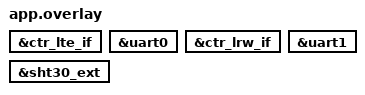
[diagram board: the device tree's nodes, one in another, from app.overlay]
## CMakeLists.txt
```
#
# Copyright (c) 2024 HARDWARIO a.s.
#
#  SPDX-License-Identifier: LicenseRef-HARDWARIO-5-Clause
#

cmake_minimum_required(VERSION 3.20.0)

set(ENV{FW_BUNDLE} "com.hardwario.chester.clime")
set(ENV{FW_VERSION} "v1.0.0")
set(ENV{FW_NAME} "CHESTER Clime")

find_package(Zephyr REQUIRED HINTS $ENV{ZEPHYR_BASE})

project(chester-clime)

add_custom_command(
    COMMAND ../../../scripts/gen-msg-key.py ../codec/cbor-decoder.yaml ../src/msg_key.h
    OUTPUT ../src/msg_key.h
    MAIN_DEPENDENCY ../codec/cbor-decoder.yaml
)

target_sources(app PRIVATE src/app_sensor.c)
target_sources(app PRIVATE src/main.c)
target_sources(app PRIVATE src/app_shell.c)
target_sources(app PRIVATE src/app_init.c)
target_sources(app PRIVATE src/app_data.c)
target_sources(app PRIVATE src/app_power.c)
target_sources(app PRIVATE src/app_send.c)
target_sources(app PRIVATE src/app_config.c)
target_sources(app PRIVATE src/app_work.c)
target_sources(app PRIVATE src/app_handler.c)
target_sources(app PRIVATE src/app_backup.c)
target_sources(app PRIVATE src/app_cbor.c)
```

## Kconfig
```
#
# Copyright (c) 2024 HARDWARIO a.s.
#
# SPDX-License-Identifier: LicenseRef-HARDWARIO-5-Clause
#

menu "Application"

# CHESTER CLIME Project | CLIME Variant 

# LTE 
config SHIELD_CTR_LTE
	bool "Enable SHIELD_CTR_LTE"
	default y 

config CTR_LTE
	default y
# LRW 
config SHIELD_CTR_LRW
	bool "Enable SHIELD_CTR_LRW"
	default y 

config CTR_LRW
	default y
# S2 
config SHIELD_CTR_S2
	bool "Enable SHIELD_CTR_S2"
	default y 

config CTR_HYGRO
	default y

endmenu

menu "Zephyr Kernel"
source "Kconfig.zephyr"
endmenu
```

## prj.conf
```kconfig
#
# Copyright (c) 2024 HARDWARIO a.s.
#
#  SPDX-License-Identifier: LicenseRef-HARDWARIO-5-Clause
#

# Configurations
CONFIG_ADC_SHELL=y
CONFIG_CTR_ACCEL=y
CONFIG_CTR_BATT=y
CONFIG_CTR_BUTTON=y
CONFIG_CTR_BLE=y
CONFIG_CTR_BUF=y
CONFIG_CTR_DEFAULTS=y
CONFIG_CTR_INFO=y
CONFIG_CTR_LED=y
CONFIG_CTR_LOG=y
CONFIG_CTR_RTC=y
CONFIG_CTR_THERM=y
CONFIG_CTR_WDOG=y
CONFIG_TINYCRYPT=y
CONFIG_TINYCRYPT_SHA256=y
CONFIG_ZCBOR=y
CONFIG_ZCBOR_STOP_ON_ERROR=y
CONFIG_CTR_LTE_CLKSYNC=y

# Extra configurations
CONFIG_ADC_TLA2021_INIT_PRIORITY=60
CONFIG_ADC_NRFX_SAADC=n
CONFIG_ADC_SHELL=n
CONFIG_NEWLIB_LIBC_NANO=n

# USER CODE BEGIN Config 
# USER CODE END Config
```

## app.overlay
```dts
/*
 * Copyright (c) 2024 HARDWARIO a.s.
 *
 * SPDX-License-Identifier: LicenseRef-HARDWARIO-5-Clause
 */

/* CHESTER CLIME Project | CLIME Variant */

/* LTE  */
&ctr_lte_if {
	status = "okay";
};

&uart0 {
	status = "okay";
};
/* LRW   */
&ctr_lrw_if {
	status = "okay";
};

&uart1 {
	status = "okay";
};
/* S2  */
&sht30_ext {
	status = "okay";
};
```

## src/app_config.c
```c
/*
 * Copyright (c) 2024 HARDWARIO a.s.
 *
 * SPDX-License-Identifier: LicenseRef-HARDWARIO-5-Clause
 */

#include "app_config.h"

/* CHESTER includes */
#include <chester/ctr_config.h>

/* Zephyr includes */
#include <zephyr/init.h>
#include <zephyr/kernel.h>
#include <zephyr/logging/log.h>
#include <zephyr/settings/settings.h>
#include <zephyr/shell/shell.h>

/* Standard includes */
#include <ctype.h>
#include <stdbool.h>
#include <stdio.h>
#include <stdlib.h>
#include <string.h>

/* USER CODE BEGIN Includes */
/* USER CODE END Includes */

LOG_MODULE_REGISTER(app_config, LOG_LEVEL_DBG);

#define SETTINGS_PFX "chester-clime"

struct app_config g_app_config;

static struct app_config m_app_config_interim = {
	.interval_sample = 60,
	.interval_aggreg = 300,
	.interval_report = 1800,
	.event_report_delay = 1,
	.event_report_rate = 30,
	.backup_report_connected = true,
	.backup_report_disconnected = true,
	.mode = APP_CONFIG_MODE_LTE,

	/* USER CODE BEGIN Struct Variables */
	/* USER CODE END Struct Variables */
};

/* USER CODE BEGIN Variables */
/* USER CODE END Variables */

static void print_app_config_mode(const struct shell *shell)
{
	const char *mode;
	switch (m_app_config_interim.mode) {
	case APP_CONFIG_MODE_NONE:
		mode = "none";
		break;
	case APP_CONFIG_MODE_LTE:
		mode = "lte";
		break;
	case APP_CONFIG_MODE_LRW:
		mode = "lrw";
		break;
	default:
		mode = "(unknown)";
		break;
	}

	shell_print(shell, "app config mode %s", mode);
}

int app_config_cmd_config_mode(const struct shell *shell, size_t argc, char **argv)
{
	if (argc == 1) {
		print_app_config_mode(shell);
		return 0;
	}

	if (argc == 2) {
		if (!strcmp("none", argv[1])) {
			m_app_config_interim.mode = APP_CONFIG_MODE_NONE;
			return 0;
		}

		if (!strcmp("lte", argv[1])) {
			m_app_config_interim.mode = APP_CONFIG_MODE_LTE;
			return 0;
		}

		if (!strcmp("lrw", argv[1])) {
			m_app_config_interim.mode = APP_CONFIG_MODE_LRW;
			return 0;
		}

		shell_error(shell, "invalid option");

		return -EINVAL;
	}

	shell_help(shell);

	return -EINVAL;
}

static void print_interval_sample(const struct shell *shell)
{
	shell_print(shell, "app config interval-sample  %d",
			m_app_config_interim.interval_sample);
}

int app_config_cmd_config_interval_sample(const struct shell *shell, size_t argc, char **argv)
{
	if (argc == 1) {
		print_interval_sample(shell);
		return 0;
	}
	if (argc == 2) {
		size_t len = strlen(argv[1]);
		for (size_t i = 0; i < len; i++) {
			if (!isdigit((int)argv[1][i])) {
				shell_error(shell, "invalid format");
				return -EINVAL;
			}
		}
		long value = strtol(argv[1], NULL, 10);
		if (value < 1 || value > 86400) {
			shell_error(shell, "invalid range");
			return -EINVAL;
		}
		m_app_config_interim.interval_sample = (int)value;
		return 0;
	}
	shell_help(shell);
	return -EINVAL;
}

static void print_interval_aggreg(const struct shell *shell)
{
	shell_print(shell, "app config interval-aggreg  %d",
			m_app_config_interim.interval_aggreg);
}

int app_config_cmd_config_interval_aggreg(const struct shell *shell, size_t argc, char **argv)
{
	if (argc == 1) {
		print_interval_aggreg(shell);
		return 0;
	}
	if (argc == 2) {
		size_t len = strlen(argv[1]);
		for (size_t i = 0; i < len; i++) {
			if (!isdigit((int)argv[1][i])) {
				shell_error(shell, "invalid format");
				return -EINVAL;
			}
		}
		long value = strtol(argv[1], NULL, 10);
		if (value < 1 || value > 86400) {
			shell_error(shell, "invalid range");
			return -EINVAL;
		}
		m_app_config_interim.interval_aggreg = (int)value;
		return 0;
	}
	shell_help(shell);
	return -EINVAL;
}

static void print_interval_report(const struct shell *shell)
{
	shell_print(shell, "app config interval-report  %d",
			m_app_config_interim.interval_report);
}

int app_config_cmd_config_interval_report(const struct shell *shell, size_t argc, char **argv)
{
	if (argc == 1) {
		print_interval_report(shell);
		return 0;
	}
	if (argc == 2) {
		size_t len = strlen(argv[1]);
		for (size_t i = 0; i < len; i++) {
			if (!isdigit((int)argv[1][i])) {
				shell_error(shell, "invalid format");
				return -EINVAL;
			}
		}
		long value = strtol(argv[1], NULL, 10);
		if (value < 30 || value > 86400) {
			shell_error(shell, "invalid range");
			return -EINVAL;
		}
		m_app_config_interim.interval_report = (int)value;
		return 0;
	}
	shell_help(shell);
	return -EINVAL;
}

static void print_hygro_t_alarm_hi_report(const struct shell *shell)
{
	shell_print(shell, "app config hygro-t-alarm-hi-report  %s",
			m_app_config_interim.hygro_t_alarm_hi_report ? "true" : "false");
}

int app_config_cmd_config_hygro_t_alarm_hi_report(const struct shell *shell, size_t argc, char **argv)
{
	if (argc == 1) {
		print_hygro_t_alarm_hi_report(shell);                                                    
		return 0;
	}
	if (argc == 2) {
		bool is_false = !strcmp(argv[1], "false");
		bool is_true = !strcmp(argv[1], "true");
		if (is_false) {
			m_app_config_interim.hygro_t_alarm_hi_report = false;
		} else if (is_true) {
			m_app_config_interim.hygro_t_alarm_hi_report = true;
		} else {
			shell_error(shell, "invalid format");
			return -EINVAL;
		}
		return 0;
	}
	shell_help(shell);
	return -EINVAL;
}

static void print_hygro_t_alarm_lo_report(const struct shell *shell)
{
	shell_print(shell, "app config hygro-t-alarm-lo-report  %s",
			m_app_config_interim.hygro_t_alarm_lo_report ? "true" : "false");
}

int app_config_cmd_config_hygro_t_alarm_lo_report(const struct shell *shell, size_t argc, char **argv)
{
	if (argc == 1) {
		print_hygro_t_alarm_lo_report(shell);                                                    
		return 0;
	}
	if (argc == 2) {
		bool is_false = !strcmp(argv[1], "false");
		bool is_true = !strcmp(argv[1], "true");
		if (is_false) {
			m_app_config_interim.hygro_t_alarm_lo_report = false;
		} else if (is_true) {
			m_app_config_interim.hygro_t_alarm_lo_report = true;
		} else {
			shell_error(shell, "invalid format");
			return -EINVAL;
		}
		return 0;
	}
	shell_help(shell);
	return -EINVAL;
}

static void print_hygro_t_alarm_hi_thr(const struct shell *shell)
{
	shell_print(shell, "app config hygro-t-alarm-hi-thr %.1f",
			m_app_config_interim.hygro_t_alarm_hi_thr);
}

int app_config_cmd_config_hygro_t_alarm_hi_thr(const struct shell *shell, size_t argc, char **argv)
{
	if (argc == 1) {
		print_hygro_t_alarm_hi_thr(shell);
		return 0;
	}
	if (argc == 2) {
		float value;
		int ret = sscanf(argv[1], "%f", &value);
		if (ret != 1) {
			shell_error(shell, "invalid value");
			return -EINVAL;
		}
		if (value < -40.0 || value > 125.0) 
		{
			shell_error(shell, "invalid range");
			return -EINVAL;
		}
		m_app_config_interim.hygro_t_alarm_hi_thr = value;
		return 0;
	}
	shell_help(shell);
	return -EINVAL;
}

static void print_hygro_t_alarm_hi_hst(const struct shell *shell)
{
	shell_print(shell, "app config hygro-t-alarm-hi-hst %.1f",
			m_app_config_interim.hygro_t_alarm_hi_hst);
}

int app_config_cmd_config_hygro_t_alarm_hi_hst(const struct shell *shell, size_t argc, char **argv)
{
	if (argc == 1) {
		print_hygro_t_alarm_hi_hst(shell);
		return 0;
	}
	if (argc == 2) {
		float value;
		int ret = sscanf(argv[1], "%f", &value);
		if (ret != 1) {
			shell_error(shell, "invalid value");
			return -EINVAL;
		}
		if (value < 0.0 || value > 100.0) 
		{
			shell_error(shell, "invalid range");
			return -EINVAL;
		}
		m_app_config_interim.hygro_t_alarm_hi_hst = value;
		return 0;
	}
	shell_help(shell);
	return -EINVAL;
}

static void print_hygro_t_alarm_lo_thr(const struct shell *shell)
{
	shell_print(shell, "app config hygro-t-alarm-lo-thr %.1f",
			m_app_config_interim.hygro_t_alarm_lo_thr);
}

int app_config_cmd_config_hygro_t_alarm_lo_thr(const struct shell *shell, size_t argc, char **argv)
{
	if (argc == 1) {
		print_hygro_t_alarm_lo_thr(shell);
		return 0;
	}
	if (argc == 2) {
		float value;
		int ret = sscanf(argv[1], "%f", &value);
		if (ret != 1) {
			shell_error(shell, "invalid value");
			return -EINVAL;
		}
		if (value < -40.0 || value > 125.0) 
		{
			shell_error(shell, "invalid range");
			return -EINVAL;
		}
		m_app_config_interim.hygro_t_alarm_lo_thr = value;
		return 0;
	}
	shell_help(shell);
	return -EINVAL;
}

static void print_hygro_t_alarm_lo_hst(const struct shell *shell)
{
	shell_print(shell, "app config hygro-t-alarm-lo-hst %.1f",
			m_app_config_interim.hygro_t_alarm_lo_hst);
}

int app_config_cmd_config_hygro_t_alarm_lo_hst(const struct shell *shell, size_t argc, char **argv)
{
	if (argc == 1) {
		print_hygro_t_alarm_lo_hst(shell);
		return 0;
	}
	if (argc == 2) {
		float value;
		int ret = sscanf(argv[1], "%f", &value);
		if (ret != 1) {
			shell_error(shell, "invalid value");
			return -EINVAL;
		}
		if (value < 0.0 || value > 100.0) 
		{
			shell_error(shell, "invalid range");
			return -EINVAL;
		}
		m_app_config_interim.hygro_t_alarm_lo_hst = value;
		return 0;
	}
	shell_help(shell);
	return -EINVAL;
}

static void print_event_report_delay(const struct shell *shell)
{
	shell_print(shell, "app config event-report-delay  %d",
			m_app_config_interim.event_report_delay);
}

int app_config_cmd_config_event_report_delay(const struct shell *shell, size_t argc, char **argv)
{
	if (argc == 1) {
		print_event_report_delay(shell);
		return 0;
	}
	if (argc == 2) {
		size_t len = strlen(argv[1]);
		for (size_t i = 0; i < len; i++) {
			if (!isdigit((int)argv[1][i])) {
				shell_error(shell, "invalid format");
				return -EINVAL;
			}
		}
		long value = strtol(argv[1], NULL, 10);
		if (value < 1 || value > 86400) {
			shell_error(shell, "invalid range");
			return -EINVAL;
		}
		m_app_config_interim.event_report_delay = (int)value;
		return 0;
	}
	shell_help(shell);
	return -EINVAL;
}

static void print_event_report_rate(const struct shell *shell)
{
	shell_print(shell, "app config event-report-rate  %d",
			m_app_config_interim.event_report_rate);
}

int app_config_cmd_config_event_report_rate(const struct shell *shell, size_t argc, char **argv)
{
	if (argc == 1) {
		print_event_report_rate(shell);
		return 0;
	}
	if (argc == 2) {
		size_t len = strlen(argv[1]);
		for (size_t i = 0; i < len; i++) {
			if (!isdigit((int)argv[1][i])) {
				shell_error(shell, "invalid format");
				return -EINVAL;
			}
		}
		long value = strtol(argv[1], NULL, 10);
		if (value < 1 || value > 3600) {
			shell_error(shell, "invalid range");
			return -EINVAL;
		}
		m_app_config_interim.event_report_rate = (int)value;
		return 0;
	}
	shell_help(shell);
	return -EINVAL;
}

static void print_backup_report_connected(const struct shell *shell)
{
	shell_print(shell, "app config backup-report-connected  %s",
			m_app_config_interim.backup_report_connected ? "true" : "false");
}

int app_config_cmd_config_backup_report_connected(const struct shell *shell, size_t argc, char **argv)
{
	if (argc == 1) {
		print_backup_report_connected(shell);                                                    
		return 0;
	}
	if (argc == 2) {
		bool is_false = !strcmp(argv[1], "false");
		bool is_true = !strcmp(argv[1], "true");
		if (is_false) {
			m_app_config_interim.backup_report_connected = false;
		} else if (is_true) {
			m_app_config_interim.backup_report_connected = true;
		} else {
			shell_error(shell, "invalid format");
			return -EINVAL;
		}
		return 0;
	}
	shell_help(shell);
	return -EINVAL;
}

static void print_backup_report_disconnected(const struct shell *shell)
{
	shell_print(shell, "app config backup-report-disconnected  %s",
			m_app_config_interim.backup_report_disconnected ? "true" : "false");
}

int app_config_cmd_config_backup_report_disconnected(const struct shell *shell, size_t argc, char **argv)
{
	if (argc == 1) {
		print_backup_report_disconnected(shell);                                                    
		return 0;
	}
	if (argc == 2) {
		bool is_false = !strcmp(argv[1], "false");
		bool is_true = !strcmp(argv[1], "true");
		if (is_false) {
			m_app_config_interim.backup_report_disconnected = false;
		} else if (is_true) {
			m_app_config_interim.backup_report_disconnected = true;
		} else {
			shell_error(shell, "invalid format");
			return -EINVAL;
		}
		return 0;
	}
	shell_help(shell);
	return -EINVAL;
}

int app_config_cmd_config_show(const struct shell *shell, size_t argc, char **argv)
{
	print_app_config_mode(shell);
	print_interval_sample(shell);
	print_interval_aggreg(shell);
	print_interval_report(shell);
	print_hygro_t_alarm_hi_report(shell);
	print_hygro_t_alarm_lo_report(shell);
	print_hygro_t_alarm_hi_thr(shell);
	print_hygro_t_alarm_hi_hst(shell);
	print_hygro_t_alarm_lo_thr(shell);
	print_hygro_t_alarm_lo_hst(shell);
	print_event_report_delay(shell);
	print_event_report_rate(shell);
	print_backup_report_connected(shell);
	print_backup_report_disconnected(shell);
	
	return 0;
}

/* USER CODE BEGIN Functions 1 */
/* USER CODE END Functions 1 */

static int h_commit(void)
{
	LOG_DBG("Loaded settings in full");
	memcpy(&g_app_config, &m_app_config_interim, sizeof(g_app_config));

	return 0;
}

static int h_set(const char *key, size_t len, settings_read_cb read_cb, void *cb_arg) 
{
	int ret;
	const char *next;
	if (settings_name_steq(key, "mode", &next) && !next) {
		if (len != sizeof(m_app_config_interim.mode)) {
			return -EINVAL;
		}
		ret = read_cb(cb_arg, &m_app_config_interim.mode, len);
		if (ret < 0) {
			LOG_ERR("Call `read_cb` failed: %d", ret);
			return ret;
		}
		return 0;
	}
	
	if (settings_name_steq(key, "interval-sample", &next) && !next) {
		if (len != sizeof(m_app_config_interim.interval_sample)) {
			return -EINVAL;
		}
		ret = read_cb(cb_arg, &m_app_config_interim.interval_sample, len);
		if (ret < 0) {
			LOG_ERR("Call `read_cb` failed: %d", ret);
			return ret;
		}
		return 0;
	}

	if (settings_name_steq(key, "interval-aggreg", &next) && !next) {
		if (len != sizeof(m_app_config_interim.interval_aggreg)) {
			return -EINVAL;
		}
		ret = read_cb(cb_arg, &m_app_config_interim.interval_aggreg, len);
		if (ret < 0) {
			LOG_ERR("Call `read_cb` failed: %d", ret);
			return ret;
		}
		return 0;
	}

	if (settings_name_steq(key, "interval-report", &next) && !next) {
		if (len != sizeof(m_app_config_interim.interval_report)) {
			return -EINVAL;
		}
		ret = read_cb(cb_arg, &m_app_config_interim.interval_report, len);
		if (ret < 0) {
			LOG_ERR("Call `read_cb` failed: %d", ret);
			return ret;
		}
		return 0;
	}

	if (settings_name_steq(key, "hygro-t-alarm-hi-report", &next) && !next) {
		if (len != sizeof(m_app_config_interim.hygro_t_alarm_hi_report)) {
			return -EINVAL;
		}
		ret = read_cb(cb_arg, &m_app_config_interim.hygro_t_alarm_hi_report, len);
		if (ret < 0) {
			LOG_ERR("Call `read_cb` failed: %d", ret);
			return ret;
		}
		return 0;
	}

	if (settings_name_steq(key, "hygro-t-alarm-lo-report", &next) && !next) {
		if (len != sizeof(m_app_config_interim.hygro_t_alarm_lo_report)) {
			return -EINVAL;
		}
		ret = read_cb(cb_arg, &m_app_config_interim.hygro_t_alarm_lo_report, len);
		if (ret < 0) {
			LOG_ERR("Call `read_cb` failed: %d", ret);
			return ret;
		}
		return 0;
	}

	if (settings_name_steq(key, "hygro-t-alarm-hi-thr", &next) && !next) {
		if (len != sizeof(m_app_config_interim.hygro_t_alarm_hi_thr)) {
			return -EINVAL;
		}
		ret = read_cb(cb_arg, &m_app_config_interim.hygro_t_alarm_hi_thr, len);
		if (ret < 0) {
			LOG_ERR("Call `read_cb` failed: %d", ret);
			return ret;
		}
		return 0;
	}

	if (settings_name_steq(key, "hygro-t-alarm-hi-hst", &next) && !next) {
		if (len != sizeof(m_app_config_interim.hygro_t_alarm_hi_hst)) {
			return -EINVAL;
		}
		ret = read_cb(cb_arg, &m_app_config_interim.hygro_t_alarm_hi_hst, len);
		if (ret < 0) {
			LOG_ERR("Call `read_cb` failed: %d", ret);
			return ret;
		}
		return 0;
	}

	if (settings_name_steq(key, "hygro-t-alarm-lo-thr", &next) && !next) {
		if (len != sizeof(m_app_config_interim.hygro_t_alarm_lo_thr)) {
			return -EINVAL;
		}
		ret = read_cb(cb_arg, &m_app_config_interim.hygro_t_alarm_lo_thr, len);
		if (ret < 0) {
			LOG_ERR("Call `read_cb` failed: %d", ret);
			return ret;
		}
		return 0;
	}

	if (settings_name_steq(key, "hygro-t-alarm-lo-hst", &next) && !next) {
		if (len != sizeof(m_app_config_interim.hygro_t_alarm_lo_hst)) {
			return -EINVAL;
		}
		ret = read_cb(cb_arg, &m_app_config_interim.hygro_t_alarm_lo_hst, len);
		if (ret < 0) {
			LOG_ERR("Call `read_cb` failed: %d", ret);
			return ret;
		}
		return 0;
	}

	if (settings_name_steq(key, "event-report-delay", &next) && !next) {
		if (len != sizeof(m_app_config_interim.event_report_delay)) {
			return -EINVAL;
		}
		ret = read_cb(cb_arg, &m_app_config_interim.event_report_delay, len);
		if (ret < 0) {
			LOG_ERR("Call `read_cb` failed: %d", ret);
			return ret;
		}
		return 0;
	}

	if (settings_name_steq(key, "event-report-rate", &next) && !next) {
		if (len != sizeof(m_app_config_interim.event_report_rate)) {
			return -EINVAL;
		}
		ret = read_cb(cb_arg, &m_app_config_interim.event_report_rate, len);
		if (ret < 0) {
			LOG_ERR("Call `read_cb` failed: %d", ret);
			return ret;
		}
		return 0;
	}

	if (settings_name_steq(key, "backup-report-connected", &next) && !next) {
		if (len != sizeof(m_app_config_interim.backup_report_connected)) {
			return -EINVAL;
		}
		ret = read_cb(cb_arg, &m_app_config_interim.backup_report_connected, len);
		if (ret < 0) {
			LOG_ERR("Call `read_cb` failed: %d", ret);
			return ret;
		}
		return 0;
	}

	if (settings_name_steq(key, "backup-report-disconnected", &next) && !next) {
		if (len != sizeof(m_app_config_interim.backup_report_disconnected)) {
			return -EINVAL;
		}
		ret = read_cb(cb_arg, &m_app_config_interim.backup_report_disconnected, len);
		if (ret < 0) {
			LOG_ERR("Call `read_cb` failed: %d", ret);
			return ret;
		}
		return 0;
	}

	/* USER CODE BEGIN Functions 2 */
	/* USER CODE END Functions 2 */

	return 0;
}

static int h_export(int (*export_func)(const char *name, const void *val, size_t val_len))
{
	int ret;
	ret = export_func("chester-clime/mode", &m_app_config_interim.mode,
					  sizeof( m_app_config_interim.mode));
	if (ret < 0) {
		return ret;
	}

	ret = export_func("chester-clime/interval-sample", &m_app_config_interim.interval_sample,
					  sizeof( m_app_config_interim.interval_sample));
	if (ret < 0) {
		return ret;
	}

	ret = export_func("chester-clime/interval-aggreg", &m_app_config_interim.interval_aggreg,
					  sizeof( m_app_config_interim.interval_aggreg));
	if (ret < 0) {
		return ret;
	}

	ret = export_func("chester-clime/interval-report", &m_app_config_interim.interval_report,
					  sizeof( m_app_config_interim.interval_report));
	if (ret < 0) {
		return ret;
	}

	ret = export_func("chester-clime/hygro-t-alarm-hi-report", &m_app_config_interim.hygro_t_alarm_hi_report,
					  sizeof( m_app_config_interim.hygro_t_alarm_hi_report));
	if (ret < 0) {
		return ret;
	}

	ret = export_func("chester-clime/hygro-t-alarm-lo-report", &m_app_config_interim.hygro_t_alarm_lo_report,
					  sizeof( m_app_config_interim.hygro_t_alarm_lo_report));
	if (ret < 0) {
		return ret;
	}

	ret = export_func("chester-clime/hygro-t-alarm-hi-thr", &m_app_config_interim.hygro_t_alarm_hi_thr,
					  sizeof( m_app_config_interim.hygro_t_alarm_hi_thr));
	if (ret < 0) {
		return ret;
	}

	ret = export_func("chester-clime/hygro-t-alarm-hi-hst", &m_app_config_interim.hygro_t_alarm_hi_hst,
					  sizeof( m_app_config_interim.hygro_t_alarm_hi_hst));
	if (ret < 0) {
		return ret;
	}

	ret = export_func("chester-clime/hygro-t-alarm-lo-thr", &m_app_config_interim.hygro_t_alarm_lo_thr,
					  sizeof( m_app_config_interim.hygro_t_alarm_lo_thr));
	if (ret < 0) {
		return ret;
	}

	ret = export_func("chester-clime/hygro-t-alarm-lo-hst", &m_app_config_interim.hygro_t_alarm_lo_hst,
					  sizeof( m_app_config_interim.hygro_t_alarm_lo_hst));
	if (ret < 0) {
		return ret;
	}

	ret = export_func("chester-clime/event-report-delay", &m_app_config_interim.event_report_delay,
					  sizeof( m_app_config_interim.event_report_delay));
	if (ret < 0) {
		return ret;
	}

	ret = export_func("chester-clime/event-report-rate", &m_app_config_interim.event_report_rate,
					  sizeof( m_app_config_interim.event_report_rate));
	if (ret < 0) {
		return ret;
	}

	ret = export_func("chester-clime/backup-report-connected", &m_app_config_interim.backup_report_connected,
					  sizeof( m_app_config_interim.backup_report_connected));
	if (ret < 0) {
		return ret;
	}

	ret = export_func("chester-clime/backup-report-disconnected", &m_app_config_interim.backup_report_disconnected,
					  sizeof( m_app_config_interim.backup_report_disconnected));
	if (ret < 0) {
		return ret;
	}

	/* USER CODE BEGIN Functions 3 */
	/* USER CODE END Functions 3 */

	return 0;
}

static int init(void) 
{
	int ret;

	LOG_INF("System initialization");

	static struct settings_handler sh = {
		.name = SETTINGS_PFX,
		.h_set = h_set,
		.h_commit = h_commit,
		.h_export = h_export,
	};

	ret = settings_register(&sh);

	if (ret < 0) {
		LOG_ERR("Call `settings_register` failed: %d", ret);
		return ret;
	}

	ret = settings_load_subtree(SETTINGS_PFX);

	if (ret < 0) {
		LOG_ERR("Call `settings_load_subtree` failed: %d", ret);
		return ret;
	}

	ctr_config_append_show(SETTINGS_PFX, app_config_cmd_config_show);

	/* USER CODE BEGIN Functions 4 */
	/* USER CODE END Functions 4 */

	return 0;
}

SYS_INIT(init, APPLICATION, CONFIG_APPLICATION_INIT_PRIORITY);
```

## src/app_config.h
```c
/*
 * Copyright (c) 2024 HARDWARIO a.s.
 *
 * SPDX-License-Identifier: LicenseRef-HARDWARIO-5-Clause
 */

#ifndef APP_CONFIG_H_
#define APP_CONFIG_H_

/* Zephyr includes */
#include <zephyr/shell/shell.h>

/* Standard includes */
#include <stdbool.h>
#include <stddef.h>

/* USER CODE BEGIN Includes */
/* USER CODE END Includes */

#ifdef __cplusplus
extern "C" {
#endif

enum app_config_mode {
	APP_CONFIG_MODE_NONE = 0,
	APP_CONFIG_MODE_LTE = 1,
	APP_CONFIG_MODE_LRW = 2,
};

struct app_config {
	enum app_config_mode mode;
	int interval_sample;
	int interval_aggreg;
	int interval_report;
	bool hygro_t_alarm_hi_report;
	bool hygro_t_alarm_lo_report;
	float hygro_t_alarm_hi_thr;
	float hygro_t_alarm_hi_hst;
	float hygro_t_alarm_lo_thr;
	float hygro_t_alarm_lo_hst;
	int event_report_delay;
	int event_report_rate;
	bool backup_report_connected;
	bool backup_report_disconnected;

	/* USER CODE BEGIN Struct Variables */
	/* USER CODE END Struct Variables */
};

extern struct app_config g_app_config;

/* USER CODE BEGIN Variables */
/* USER CODE END Variables */

int app_config_cmd_config_mode(const struct shell *shell, size_t argc, char **argv);
int app_config_cmd_config_show(const struct shell *shell, size_t argc, char **argv);
int app_config_cmd_config_interval_sample(const struct shell *shell, size_t argc, char **argv);
int app_config_cmd_config_interval_aggreg(const struct shell *shell, size_t argc, char **argv);
int app_config_cmd_config_interval_report(const struct shell *shell, size_t argc, char **argv);
int app_config_cmd_config_hygro_t_alarm_hi_report(const struct shell *shell, size_t argc, char **argv);
int app_config_cmd_config_hygro_t_alarm_lo_report(const struct shell *shell, size_t argc, char **argv);
int app_config_cmd_config_hygro_t_alarm_hi_thr(const struct shell *shell, size_t argc, char **argv);
int app_config_cmd_config_hygro_t_alarm_hi_hst(const struct shell *shell, size_t argc, char **argv);
int app_config_cmd_config_hygro_t_alarm_lo_thr(const struct shell *shell, size_t argc, char **argv);
int app_config_cmd_config_hygro_t_alarm_lo_hst(const struct shell *shell, size_t argc, char **argv);
int app_config_cmd_config_event_report_delay(const struct shell *shell, size_t argc, char **argv);
int app_config_cmd_config_event_report_rate(const struct shell *shell, size_t argc, char **argv);
int app_config_cmd_config_backup_report_connected(const struct shell *shell, size_t argc, char **argv);
int app_config_cmd_config_backup_report_disconnected(const struct shell *shell, size_t argc, char **argv);

/* USER CODE BEGIN Functions 1 */
/* USER CODE END Functions 1 */

#ifdef __cplusplus
}
#endif

#endif /* APP_CONFIG_H_ */
```

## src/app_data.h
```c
/*
 * Copyright (c) 2023 HARDWARIO a.s.
 *
 * SPDX-License-Identifier: LicenseRef-HARDWARIO-5-Clause
 */

#ifndef APP_DATA_H_
#define APP_DATA_H_

/* CHESTER includes */
#include <chester/ctr_lte.h>

/* Standard includes */
#include <stdbool.h>
#include <stdint.h>

/* TODO Delete */
#include <zephyr/kernel.h>

#define APP_DATA_MAX_MEASUREMENTS  32
#define APP_DATA_MAX_SAMPLES       32
#define APP_DATA_MAX_TAMPER_EVENTS 32
#define APP_DATA_MAX_BACKUP_EVENTS 32
#define APP_DATA_MAX_HYGRO_EVENTS  32

#if defined(CONFIG_SHIELD_CTR_DS18B20)
#define APP_DATA_W1_THERM_COUNT       10
#define APP_DATA_W1_THERM_MAX_SAMPLES 128
#endif /* defined(CONFIG_SHIELD_CTR_DS18B20) */

#if (defined(CONFIG_SHIELD_CTR_RTD_A) && !defined(CONFIG_SHIELD_CTR_RTD_B)) ||                     \
	(!defined(CONFIG_SHIELD_CTR_RTD_A) && defined(CONFIG_SHIELD_CTR_RTD_B))
#define APP_DATA_RTD_THERM_COUNT 2
#elif defined(CONFIG_SHIELD_CTR_RTD_A) && defined(CONFIG_SHIELD_CTR_RTD_B)
#define APP_DATA_RTD_THERM_COUNT 4
#endif

#define APP_DATA_SOIL_SENSOR_COUNT 10

#ifdef __cplusplus
extern "C" {
#endif

#if defined(CONFIG_APP_TAMPER)
struct app_data_tamper_event {
	int64_t timestamp;
	bool activated;
};

struct app_data_tamper {
	bool activated;
	int event_count;
	struct app_data_tamper_event events[APP_DATA_MAX_TAMPER_EVENTS];
};
#endif /* defined(CONFIG_APP_TAMPER) */

#if defined(CONFIG_SHIELD_CTR_Z)
struct app_data_backup_event {
	int64_t timestamp;
	bool connected;
};

struct app_data_backup {
	float line_voltage;
	float battery_voltage;
	bool line_present;
	int event_count;
	struct app_data_backup_event events[APP_DATA_MAX_BACKUP_EVENTS];
};
#endif /* defined(CONFIG_SHIELD_CTR_Z) */

struct app_data_aggreg {
	float min;
	float max;
	float avg;
	float mdn;
};

#if defined(CONFIG_SHIELD_CTR_S1)
struct app_data_iaq_measurement {
	struct app_data_aggreg temperature;
	struct app_data_aggreg humidity;
	struct app_data_aggreg illuminance;
	struct app_data_aggreg altitude;
	struct app_data_aggreg pressure;
	struct app_data_aggreg co2_conc;

	int press_count;
	int motion_count;
};

struct app_data_iaq {
	atomic_t press_count;
	atomic_t motion_count;

	int sample_count;
	float samples_temperature[APP_DATA_MAX_SAMPLES];
	float samples_humidity[APP_DATA_MAX_SAMPLES];
	float samples_illuminance[APP_DATA_MAX_SAMPLES];
	float samples_altitude[APP_DATA_MAX_SAMPLES];
	float samples_pressure[APP_DATA_MAX_SAMPLES];
	float samples_co2_conc[APP_DATA_MAX_SAMPLES];

	int measurement_count;
	struct app_data_iaq_measurement measurements[APP_DATA_MAX_MEASUREMENTS];

	int64_t timestamp;
};
#endif /* defined(CONFIG_SHIELD_CTR_S1) */

#if defined(CONFIG_SHIELD_CTR_S2)

enum app_data_hygro_event_type {
	APP_DATA_HYGRO_EVENT_TYPE_ALARM_HI_ACTIVATED,
	APP_DATA_HYGRO_EVENT_TYPE_ALARM_HI_DEACTIVATED,
	APP_DATA_HYGRO_EVENT_TYPE_ALARM_LO_ACTIVATED,
	APP_DATA_HYGRO_EVENT_TYPE_ALARM_LO_DEACTIVATED,
};

struct app_data_hygro_event {
	int64_t timestamp;
	enum app_data_hygro_event_type type;
	float value;
};

struct app_data_hygro_measurement {
	struct app_data_aggreg temperature;
	struct app_data_aggreg humidity;
};

struct app_data_hygro {
	float last_sample_temperature;
	float last_sample_humidity;

	int event_count;
	struct app_data_hygro_event events[APP_DATA_MAX_HYGRO_EVENTS];

	bool alarm_hi_active;
	bool alarm_lo_active;

	int sample_count;
	float samples_temperature[APP_DATA_MAX_SAMPLES];
	float samples_humidity[APP_DATA_MAX_SAMPLES];

	int measurement_count;
	struct app_data_hygro_measurement measurements[APP_DATA_MAX_MEASUREMENTS];

	int64_t timestamp;
};
#endif /* defined(CONFIG_SHIELD_CTR_S2) */

#if defined(CONFIG_SHIELD_CTR_DS18B20)
struct app_data_w1_therm_measurement {
	struct app_data_aggreg temperature;
};

struct app_data_w1_therm_sensor {
	uint64_t serial_number;

	float last_sample_temperature;

	int sample_count;
	float samples_temperature[APP_DATA_MAX_SAMPLES];

	int measurement_count;
	struct app_data_w1_therm_measurement measurements[APP_DATA_MAX_MEASUREMENTS];
};

struct app_data_w1_therm {
	struct app_data_w1_therm_sensor sensor[APP_DATA_W1_THERM_COUNT];

	int64_t timestamp;
	atomic_t sample;
	atomic_t aggreg;
};
#endif /* defined(CONFIG_SHIELD_CTR_DS18B20) */

#if defined(CONFIG_SHIELD_CTR_RTD_A) || defined(CONFIG_SHIELD_CTR_RTD_B)
struct app_data_rtd_therm_measurement {
	struct app_data_aggreg temperature;
};

struct app_data_rtd_therm_sensor {
	float last_sample_temperature;

	int sample_count;
	float samples_temperature[APP_DATA_MAX_SAMPLES];

	int measurement_count;
	struct app_data_rtd_therm_measurement measurements[APP_DATA_MAX_MEASUREMENTS];
};

struct app_data_rtd_therm {
	struct app_data_rtd_therm_sensor sensor[APP_DATA_RTD_THERM_COUNT];

	int64_t timestamp;
};
#endif /* defined(CONFIG_SHIELD_CTR_RTD_A) || defined(CONFIG_SHIELD_CTR_RTD_B) */

#if defined(CONFIG_SHIELD_CTR_SOIL_SENSOR)

struct app_data_soil_sensor_measurement {
	struct app_data_aggreg temperature;
	struct app_data_aggreg moisture;
};

struct app_data_soil_sensor_sensor {
	uint64_t serial_number;

	int sample_count;
	float samples_temperature[APP_DATA_MAX_SAMPLES];
	float samples_moisture[APP_DATA_MAX_SAMPLES];

	int measurement_count;
	struct app_data_soil_sensor_measurement measurements[APP_DATA_MAX_MEASUREMENTS];
};

struct app_data_soil_sensor {
	struct app_data_soil_sensor_sensor sensor[APP_DATA_SOIL_SENSOR_COUNT];
	int64_t timestamp;
};

#endif /* defined(CONFIG_SHIELD_CTR_SOIL_SENSOR) */

struct app_data {
	float system_voltage_rest;
	float system_voltage_load;
	float system_current_load;
	float therm_temperature;
	float accel_acceleration_x;
	float accel_acceleration_y;
	float accel_acceleration_z;
	int accel_orientation;

#if defined(CONFIG_APP_TAMPER)
	struct app_data_tamper tamper;
#endif /* defined(CONFIG_APP_TAMPER) */

#if defined(CONFIG_SHIELD_CTR_Z)
	struct app_data_backup backup;
#endif /* defined(CONFIG_SHIELD_CTR_Z) */

#if defined(CONFIG_SHIELD_CTR_S1)
	struct app_data_iaq iaq;
#endif /* defined(CONFIG_SHIELD_CTR_S1) */

#if defined(CONFIG_SHIELD_CTR_S2)
	struct app_data_hygro hygro;
#endif /* defined(CONFIG_SHIELD_CTR_S2) */

#if defined(CONFIG_SHIELD_CTR_DS18B20)
	struct app_data_w1_therm w1_therm;
#endif /* defined(CONFIG_SHIELD_CTR_DS18B20) */

#if defined(CONFIG_SHIELD_CTR_RTD_A) || defined(CONFIG_SHIELD_CTR_RTD_B)
	struct app_data_rtd_therm rtd_therm;
#endif /* defined(CONFIG_SHIELD_CTR_RTD_A) || defined(CONFIG_SHIELD_CTR_RTD_B) */

#if defined(CONFIG_SHIELD_CTR_SOIL_SENSOR)
	struct app_data_soil_sensor soil_sensor;
#endif /* defined(CONFIG_SHIELD_CTR_SOIL_SENSOR) */
};

extern struct app_data g_app_data;

/* TODO Delete */
extern struct k_mutex g_app_data_lte_eval_mut;
extern bool g_app_data_lte_eval_valid;
extern struct ctr_lte_eval g_app_data_lte_eval;

void app_data_lock(void);
void app_data_unlock(void);

#ifdef __cplusplus
}
#endif

#endif /* APP_DATA_H_ */
```

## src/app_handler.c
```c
/*
 * Copyright (c) 2023 HARDWARIO a.s.
 *
 * SPDX-License-Identifier: LicenseRef-HARDWARIO-5-Clause
 */

#include "app_backup.h"
#include "app_config.h"
#include "app_data.h"
#include "app_handler.h"
#include "app_init.h"
#include "app_send.h"
#include "app_work.h"

/* CHESTER includes */
#include <chester/ctr_button.h>
#include <chester/ctr_led.h>
#include <chester/ctr_lrw.h>
#include <chester/ctr_lte.h>
#include <chester/ctr_rtc.h>
#include <chester/drivers/ctr_x4.h>
#include <chester/drivers/ctr_z.h>

/* Zephyr includes */
#include <zephyr/kernel.h>
#include <zephyr/logging/log.h>
#include <zephyr/sys/reboot.h>

/* Standard includes */
#include <math.h>
#include <stdbool.h>
#include <stddef.h>

LOG_MODULE_REGISTER(app_handler, LOG_LEVEL_DBG);

void app_handler_lrw(enum ctr_lrw_event event, union ctr_lrw_event_data *data, void *param)
{
	int ret;

	switch (event) {
	case CTR_LRW_EVENT_FAILURE:
		LOG_INF("Event `CTR_LRW_EVENT_FAILURE`");
		ret = ctr_lrw_start(NULL);
		if (ret) {
			LOG_ERR("Call `ctr_lrw_start` failed: %d", ret);
		}
		break;
	case CTR_LRW_EVENT_START_OK:
		LOG_INF("Event `CTR_LRW_EVENT_START_OK`");
		ret = ctr_lrw_join(NULL);
		if (ret) {
			LOG_ERR("Call `ctr_lrw_join` failed: %d", ret);
		}
		break;
	case CTR_LRW_EVENT_START_ERR:
		LOG_INF("Event `CTR_LRW_EVENT_START_ERR`");
		break;
	case CTR_LRW_EVENT_JOIN_OK:
		LOG_INF("Event `CTR_LRW_EVENT_JOIN_OK`");
		break;
	case CTR_LRW_EVENT_JOIN_ERR:
		LOG_INF("Event `CTR_LRW_EVENT_JOIN_ERR`");
		break;
	case CTR_LRW_EVENT_SEND_OK:
		LOG_INF("Event `CTR_LRW_EVENT_SEND_OK`");
		break;
	case CTR_LRW_EVENT_SEND_ERR:
		LOG_INF("Event `CTR_LRW_EVENT_SEND_ERR`");
		break;
	default:
		LOG_WRN("Unknown event: %d", event);
	}
}

static void start(void)
{
	int ret;

	ret = ctr_lte_start(NULL);
	if (ret) {
		LOG_ERR("Call `ctr_lte_start` failed: %d", ret);
		k_oops();
	}
}

static void attach(void)
{
	int ret;

	ret = ctr_lte_attach(NULL);
	if (ret) {
		LOG_ERR("Call `ctr_lte_attach` failed: %d", ret);
		k_oops();
	}
}

void app_handler_lte(enum ctr_lte_event event, union ctr_lte_event_data *data, void *param)
{
	switch (event) {
	case CTR_LTE_EVENT_FAILURE:
		LOG_ERR("Event `CTR_LTE_EVENT_FAILURE`");
		start();
		break;

	case CTR_LTE_EVENT_START_OK:
		LOG_INF("Event `CTR_LTE_EVENT_START_OK`");
		attach();
		break;

	case CTR_LTE_EVENT_START_ERR:
		LOG_ERR("Event `CTR_LTE_EVENT_START_ERR`");
		start();
		break;

	case CTR_LTE_EVENT_ATTACH_OK:
		LOG_INF("Event `CTR_LTE_EVENT_ATTACH_OK`");
		k_sem_give(&g_app_init_sem);
		break;

	case CTR_LTE_EVENT_ATTACH_ERR:
		LOG_ERR("Event `CTR_LTE_EVENT_ATTACH_ERR`");
		start();
		break;

	case CTR_LTE_EVENT_DETACH_OK:
		LOG_INF("Event `CTR_LTE_EVENT_DETACH_OK`");
		break;

	case CTR_LTE_EVENT_DETACH_ERR:
		LOG_ERR("Event `CTR_LTE_EVENT_DETACH_ERR`");
		start();
		break;

	case CTR_LTE_EVENT_EVAL_OK:
		LOG_INF("Event `CTR_LTE_EVENT_EVAL_OK`");

		struct ctr_lte_eval *eval = &data->eval_ok.eval;

		LOG_DBG("EEST: %d", eval->eest);
		LOG_DBG("ECL: %d", eval->ecl);
		LOG_DBG("RSRP: %d", eval->rsrp);
		LOG_DBG("RSRQ: %d", eval->rsrq);
		LOG_DBG("SNR: %d", eval->snr);
		LOG_DBG("PLMN: %d", eval->plmn);
		LOG_DBG("CID: %d", eval->cid);
		LOG_DBG("BAND: %d", eval->band);
		LOG_DBG("EARFCN: %d", eval->earfcn);

		k_mutex_lock(&g_app_data_lte_eval_mut, K_FOREVER);
		memcpy(&g_app_data_lte_eval, &data->eval_ok.eval, sizeof(g_app_data_lte_eval));
		g_app_data_lte_eval_valid = true;
		k_mutex_unlock(&g_app_data_lte_eval_mut);

		break;

	case CTR_LTE_EVENT_EVAL_ERR:
		LOG_ERR("Event `CTR_LTE_EVENT_EVAL_ERR`");

		k_mutex_lock(&g_app_data_lte_eval_mut, K_FOREVER);
		g_app_data_lte_eval_valid = false;
		k_mutex_unlock(&g_app_data_lte_eval_mut);

		break;

	case CTR_LTE_EVENT_SEND_OK:
		LOG_INF("Event `CTR_LTE_EVENT_SEND_OK`");
		break;

	case CTR_LTE_EVENT_SEND_ERR:
		LOG_ERR("Event `CTR_LTE_EVENT_SEND_ERR`");
		start();
		break;

	default:
		LOG_WRN("Unknown event: %d", event);
		return;
	}
}

#if defined(CONFIG_SHIELD_CTR_S1)
void ctr_s1_event_handler(const struct device *dev, enum ctr_s1_event event, void *user_data)
{
	int ret;

	switch (event) {
	case CTR_S1_EVENT_DEVICE_RESET:
		LOG_INF("Event `CTR_S1_EVENT_DEVICE_RESET`");

		ret = ctr_s1_apply(dev);
		if (ret) {
			LOG_ERR("Call `ctr_s1_apply` failed: %d", ret);
			k_oops();
		}

		ret = ctr_s1_set_motion_sensitivity(dev, CTR_S1_PIR_SENSITIVITY_MEDIUM);
		if (ret) {
			LOG_ERR("Call `ctr_s1_set_motion_sensitivity` failed: %d", ret);
			k_oops();
		}

		break;

	case CTR_S1_EVENT_BUTTON_PRESSED:
		LOG_INF("Event `CTR_S1_EVENT_BUTTON_PRESSED`");

		atomic_inc(&g_app_data.iaq.press_count);

		struct ctr_s1_led_param param_led = {
			.brightness = CTR_S1_LED_BRIGHTNESS_HIGH,
			.command = CTR_S1_LED_COMMAND_1X_1_1,
			.pattern = CTR_S1_LED_PATTERN_NONE,
		};

		ret = ctr_s1_set_led(dev, CTR_S1_LED_CHANNEL_B, &param_led);
		if (ret) {
			LOG_ERR("Call `ctr_s1_set_led` failed: %d", ret);
			k_oops();
		}

		struct ctr_s1_buzzer_param param_buzzer = {
			.command = CTR_S1_BUZZER_COMMAND_1X_1_1,
			.pattern = CTR_S1_BUZZER_PATTERN_NONE,
		};

		ret = ctr_s1_set_buzzer(dev, &param_buzzer);
		if (ret) {
			LOG_ERR("Call `ctr_s1_set_buzzer` failed: %d", ret);
			k_oops();
		}

		ret = ctr_s1_apply(dev);
		if (ret) {
			LOG_ERR("Call `ctr_s1_apply` failed: %d", ret);
			k_oops();
		}

		app_work_send();

		break;

	case CTR_S1_EVENT_BUTTON_CLICKED:
		LOG_INF("Event `CTR_S1_EVENT_BUTTON_CLICKED`");
		break;

	case CTR_S1_EVENT_BUTTON_HOLD:
		LOG_INF("Event `CTR_S1_EVENT_BUTTON_HOLD`");
		break;

	case CTR_S1_EVENT_BUTTON_RELEASED:
		LOG_INF("Event `CTR_S1_EVENT_BUTTON_RELEASED`");
		break;

	case CTR_S1_EVENT_MOTION_DETECTED:
		LOG_INF("Event `CTR_S1_EVENT_MOTION_DETECTED`");

		atomic_inc(&g_app_data.iaq.motion_count);

		int motion_count;
		ret = ctr_s1_read_motion_count(dev, &motion_count);
		if (ret) {
			LOG_ERR("Call `ctr_s1_read_motion_count` failed: %d", ret);
			k_oops();
		}

		LOG_INF("Motion count: %d", motion_count);

		break;

	default:
		break;
	}
}
#endif /* defined(CONFIG_SHIELD_CTR_S1) */

#if defined(CONFIG_SHIELD_CTR_Z)

void app_handler_ctr_z(const struct device *dev, enum ctr_z_event backup_event, void *param)
{
	int ret;

	if (backup_event != CTR_Z_EVENT_DC_CONNECTED &&
	    backup_event != CTR_Z_EVENT_DC_DISCONNECTED) {
		return;
	}

	struct app_data_backup *backup = &g_app_data.backup;

	app_work_backup_update();

	app_data_lock();

	backup->line_present = backup_event == CTR_Z_EVENT_DC_CONNECTED;

	if (backup->event_count < APP_DATA_MAX_BACKUP_EVENTS) {
		struct app_data_backup_event *event = &backup->events[backup->event_count];

		ret = ctr_rtc_get_ts(&event->timestamp);
		if (ret) {
			LOG_ERR("Call `ctr_rtc_get_ts` failed: %d", ret);
			app_data_unlock();
			return;
		}

		event->connected = backup->line_present;
		backup->event_count++;

		LOG_INF("Event count: %d", backup->event_count);
	} else {
		LOG_WRN("Measurement full");
		app_data_unlock();
		return;
	}

	LOG_INF("Backup: %d", (int)backup->line_present);

	if (g_app_config.backup_report_connected && backup_event == CTR_Z_EVENT_DC_CONNECTED) {
		app_work_send_with_rate_limit();
	}

	if (g_app_config.backup_report_disconnected &&
	    backup_event == CTR_Z_EVENT_DC_DISCONNECTED) {
		app_work_send_with_rate_limit();
	}

	app_data_unlock();
}

#endif /* defined(CONFIG_SHIELD_CTR_Z) */

#if defined(CONFIG_CTR_BUTTON)

static void app_load_timer_handler(struct k_timer *timer)
{
	ctr_led_set(CTR_LED_CHANNEL_LOAD, 0);
}

K_TIMER_DEFINE(app_load_timer, app_load_timer_handler, NULL);

void app_handler_ctr_button(enum ctr_button_channel chan, enum ctr_button_event ev, int val,
			    void *user_data)
{
	int ret;

	if (chan != CTR_BUTTON_CHANNEL_INT) {
		return;
	}

	if (ev == CTR_BUTTON_EVENT_CLICK) {
		for (int i = 0; i < val; i++) {
			ret = ctr_led_set(CTR_LED_CHANNEL_Y, true);
			if (ret) {
				LOG_ERR("Call `ctr_led_set` failed: %d", ret);
				return;
			}

			k_sleep(K_MSEC(50));
			ret = ctr_led_set(CTR_LED_CHANNEL_Y, false);
			if (ret) {
				LOG_ERR("Call `ctr_led_set` failed: %d", ret);
				return;
			}

			k_sleep(K_MSEC(200));
		}

		switch (val) {
		case 1:
			app_work_send();
			break;
		case 2:
			app_work_sample();
			break;
		case 3:
			app_work_sample();
			app_work_aggreg();
			app_work_send();
			break;
		case 4:
			sys_reboot(SYS_REBOOT_COLD);
			break;
		case 5:
			ret = ctr_led_set(CTR_LED_CHANNEL_LOAD, 1);
			if (ret) {
				LOG_ERR("Call `ctr_led_set` failed: %d", ret);
				return;
			}
			k_timer_start(&app_load_timer, K_MINUTES(2), K_FOREVER);
			break;
		}
	}
}

#endif /* defined(CONFIG_CTR_BUTTON) */

#if defined(CONFIG_SHIELD_CTR_X4_A) || defined(CONFIG_SHIELD_CTR_X4_B)

void app_handler_ctr_x4(const struct device *dev, enum ctr_x4_event event, void *user_data)
{
	switch (event) {
	case CTR_X4_EVENT_LINE_CONNECTED:
		LOG_INF("Line connected");
		break;
	case CTR_X4_EVENT_LINE_DISCONNECTED:
		LOG_INF("Line disconnected");
		break;
	default:
		LOG_ERR("Unknown event: %d", event);
		k_oops();
	}

	int ret = app_send_lrw_x4_line_alert(event == CTR_X4_EVENT_LINE_CONNECTED ? BIT(0) : 0);
	if (ret) {
		LOG_ERR("Call `app_send_lrw_x4_line_alert` failed: %d", ret);
		return;
	}
}

#endif /* defined(CONFIG_SHIELD_CTR_X4_A) || defined(CONFIG_SHIELD_CTR_X4_B)*/
```

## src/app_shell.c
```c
/*
 * Copyright (c) 2024 HARDWARIO a.s.
 *
 * SPDX-License-Identifier: LicenseRef-HARDWARIO-5-Clause
 */

#include "app_config.h"
#include "app_work.h"

/* Zephyr includes */
#include <zephyr/kernel.h>
#include <zephyr/logging/log.h>
#include <zephyr/shell/shell.h>

/* Standard includes */
#include <errno.h>
#include <stdlib.h>

/* USER CODE BEGIN Includes */
/* USER CODE END Includes */

LOG_MODULE_REGISTER(app_shell, LOG_LEVEL_INF);

static int cmd_sample(const struct shell *shell, size_t argc, char **argv)
{
	if (argc > 1) {
		shell_error(shell, "unknown parameter: %s", argv[1]);
		shell_help(shell);
		return -EINVAL;
	}

	app_work_sample();

	return 0;
}

static int cmd_send(const struct shell *shell, size_t argc, char **argv)
{
	if (argc > 1) {
		shell_error(shell, "unknown parameter: %s", argv[1]);
		shell_help(shell);
		return -EINVAL;
	}

	app_work_send();

	return 0;
}

static int cmd_aggreg(const struct shell *shell, size_t argc, char **argv)
{
	if (argc > 1) {
		shell_error(shell, "unknown parameter: %s", argv[1]);
		shell_help(shell);
		return -EINVAL;
	}

	app_work_aggreg();

	return 0;
}

static int print_help(const struct shell *shell, size_t argc, char **argv)
{
	if (argc > 1) {
		shell_error(shell, "command not found: %s", argv[1]);
		shell_help(shell);
		return -EINVAL;
	}

	shell_help(shell);
	return 0;
}

/* clang-format off */

SHELL_STATIC_SUBCMD_SET_CREATE(
	sub_app_config,
   
	SHELL_CMD_ARG(show, NULL,
				  "List current configuration.",
				  app_config_cmd_config_show, 1, 0),
	
	SHELL_CMD_ARG(mode, NULL,
				  "Get/Set communication mode (None/LTE/LoRaWAN) ('none', 'lte', 'lrw').",
				  app_config_cmd_config_mode, 1, 1),
	
	SHELL_CMD_ARG(interval-sample, NULL,
				  "Get/Set sample interval in seconds (format: <1-86400>).",
				  app_config_cmd_config_interval_sample, 1, 1),
	
	SHELL_CMD_ARG(interval-aggreg, NULL,
				  "Get/Set aggregate interval in seconds (format: <1-86400>).",
				  app_config_cmd_config_interval_aggreg, 1, 1),
	
	SHELL_CMD_ARG(interval-report, NULL,
				  "Get/Set report interval in seconds (format: <30-86400>).",
				  app_config_cmd_config_interval_report, 1, 1),
	
	SHELL_CMD_ARG(hygro-t-alarm-hi-report, NULL,
				  "Get/Set report when hygro high temperature alarm is crossed (format: true, false).",
				  app_config_cmd_config_hygro_t_alarm_hi_report, 1, 1),
	
	SHELL_CMD_ARG(hygro-t-alarm-lo-report, NULL,
				  "Get/Set report when hygro low temperature alarm is crossed (format: true, false).",
				  app_config_cmd_config_hygro_t_alarm_lo_report, 1, 1),
	
	SHELL_CMD_ARG(hygro-t-alarm-hi-thr, NULL,
				  "Get/Set hygro high temperature alarm threshold (format: <-40.0..125.0>).",
				  app_config_cmd_config_hygro_t_alarm_hi_thr, 1, 1),
	
	SHELL_CMD_ARG(hygro-t-alarm-hi-hst, NULL,
				  "Get/Set hygro high temperature alarm hysteresis (format: <0.0..100.0>).",
				  app_config_cmd_config_hygro_t_alarm_hi_hst, 1, 1),
	
	SHELL_CMD_ARG(hygro-t-alarm-lo-thr, NULL,
				  "Get/Set hygro low temperature alarm threshold (format: <-40.0..125.0>).",
				  app_config_cmd_config_hygro_t_alarm_lo_thr, 1, 1),
	
	SHELL_CMD_ARG(hygro-t-alarm-lo-hst, NULL,
				  "Get/Set hygro low temperature alarm hysteresis (format: <0.0..100.0>).",
				  app_config_cmd_config_hygro_t_alarm_lo_hst, 1, 1),
	
	SHELL_CMD_ARG(event-report-delay, NULL,
				  "Get/Set event report delay in seconds (format: <1-86400>).",
				  app_config_cmd_config_event_report_delay, 1, 1),
	
	SHELL_CMD_ARG(event-report-rate, NULL,
				  "Get/Set event report rate in reports per hour (format: <1-3600>).",
				  app_config_cmd_config_event_report_rate, 1, 1),
	
	SHELL_CMD_ARG(backup-report-connected, NULL,
				  "Get/Set report when backup is active (format: true, false).",
				  app_config_cmd_config_backup_report_connected, 1, 1),
	
	SHELL_CMD_ARG(backup-report-disconnected, NULL,
				  "Get/Set report when backup is inactive (format: true, false).",
				  app_config_cmd_config_backup_report_disconnected, 1, 1),
	
	/* USER CODE BEGIN Functions 1 */
	/* USER CODE END Functions 1 */

	SHELL_SUBCMD_SET_END
);

SHELL_STATIC_SUBCMD_SET_CREATE(
	sub_app,

	SHELL_CMD_ARG(config, &sub_app_config, "Configuration commands.",
				  print_help, 1, 0),
		
	SHELL_SUBCMD_SET_END

	/* USER CODE BEGIN Functions 2 */
	/* USER CODE END Functions 2 */
);

SHELL_CMD_REGISTER(app, &sub_app, "Application commands.", print_help);

SHELL_CMD_REGISTER(sample, NULL,"Sample immediately.", cmd_sample);
SHELL_CMD_REGISTER(send, NULL,"Send data immediately.", cmd_send);
SHELL_CMD_REGISTER(aggreg, NULL,"Aggregate data immediately", cmd_aggreg);

/* USER CODE BEGIN Functions 3 */
/* USER CODE END Functions 3 */

/* clang-format on */
```
